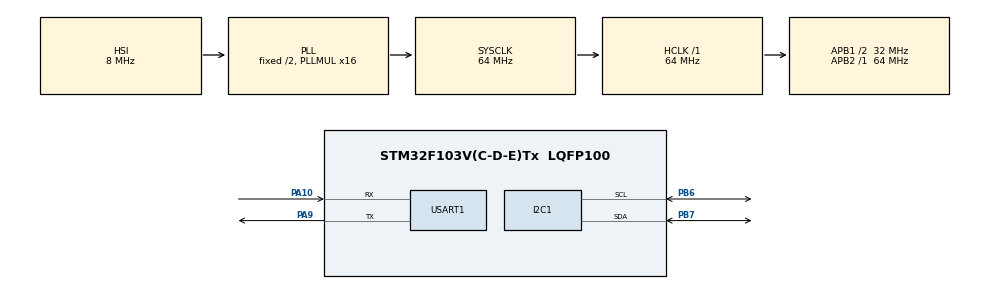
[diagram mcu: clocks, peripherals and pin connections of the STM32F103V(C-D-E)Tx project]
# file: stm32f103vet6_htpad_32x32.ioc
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Dma.Request0=USART1_RX
Dma.USART1_RX.0.Direction=DMA_PERIPH_TO_MEMORY
Dma.USART1_RX.0.Instance=DMA1_Channel5
Dma.USART1_RX.0.MemDataAlignment=DMA_MDATAALIGN_BYTE
Dma.USART1_RX.0.MemInc=DMA_MINC_ENABLE
Dma.USART1_RX.0.Mode=DMA_NORMAL
Dma.USART1_RX.0.PeriphDataAlignment=DMA_PDATAALIGN_BYTE
Dma.USART1_RX.0.PeriphInc=DMA_PINC_DISABLE
Dma.USART1_RX.0.Priority=DMA_PRIORITY_LOW
I2C1.I2C_Mode=I2C_Standard
I2C1.OwnAddress=0x1A
Mcu.Family=STM32F1
Mcu.Name=STM32F103V(C-D-E)Tx
Mcu.Package=LQFP100
NVIC.DMA1_Channel5_IRQn=true\:0\:0\:false\:false\:true\:false\:true\:true
NVIC.PriorityGroup=NVIC_PRIORITYGROUP_4
NVIC.TIM3_IRQn=true\:0\:0\:false\:false\:true\:true\:true\:true
NVIC.USART1_IRQn=true\:0\:0\:false\:false\:true\:true\:true\:true
PA10.Mode=Asynchronous
PA10.Signal=USART1_RX
PA9.Mode=Asynchronous
PA9.Signal=USART1_TX
PB6.Mode=I2C
PB6.Signal=I2C1_SCL
PB7.Mode=I2C
PB7.Signal=I2C1_SDA
ProjectManager.HeapSize=0x200
ProjectManager.StackSize=0x400
ProjectManager.TargetToolchain=STM32CubeIDE
RCC.AHBFreq_Value=64000000
RCC.APB1CLKDivider=RCC_HCLK_DIV2
RCC.APB1Freq_Value=32000000
RCC.APB1TimFreq_Value=64000000
RCC.APB2Freq_Value=64000000
RCC.APB2TimFreq_Value=64000000
RCC.HCLKFreq_Value=64000000
RCC.PLLMUL=RCC_PLL_MUL16
RCC.SYSCLKFreq_VALUE=64000000
RCC.SYSCLKSource=RCC_SYSCLKSOURCE_PLLCLK
RCC.USBFreq_Value=64000000
TIM3.Prescaler=64
USART1.VirtualMode=VM_ASYNC
VP_TIM3_VS_ClockSourceINT.Mode=Internal
board=custom

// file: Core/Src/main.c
/* USER CODE BEGIN Header */
/**
  ******************************************************************************
  * @file           : main.c
  * @brief          : Main program body
  ******************************************************************************
  * @attention
  *
  * Copyright (c) 2025 STMicroelectronics.
  * All rights reserved.
  *
  * This software is licensed under terms that can be found in the LICENSE file
  * in the root directory of this software component.
  * If no LICENSE file comes with this software, it is provided AS-IS.
  *
  ******************************************************************************
  */
/* USER CODE END Header */
#include "main.h"
#include "dma.h"
#include "i2c.h"
#include "tim.h"
#include "usart.h"
#include "gpio.h"

/* USER CODE BEGIN Includes */
#include "htpad_32x32.h"
#include <stdio.h>
#include "i2c_scan.h"
#include "uart_printf.h"
/* USER CODE END Includes */

void SystemClock_Config(void);

int main(void)
{

  /* MCU Configuration--------------------------------------------------------*/

  /* Reset of all peripherals, Initializes the Flash interface and the Systick. */
  HAL_Init();

  /* Configure the system clock */
  SystemClock_Config();

  /* Initialize all configured peripherals */
  MX_GPIO_Init();
  MX_DMA_Init();
  MX_I2C1_Init();
  MX_USART1_UART_Init();
  MX_TIM3_Init();
  /* USER CODE BEGIN 2 */
  printf("Application start!\n");
  uart_start_receive();

  setup();
  /* USER CODE END 2 */

  /* Infinite loop */
  /* USER CODE BEGIN WHILE */
  while (1)
  {
	  loop();
    /* USER CODE END WHILE */

  }
}

void SystemClock_Config(void)
{
  RCC_OscInitTypeDef RCC_OscInitStruct = {0};
  RCC_ClkInitTypeDef RCC_ClkInitStruct = {0};

  /** Initializes the RCC Oscillators according to the specified parameters
  * in the RCC_OscInitTypeDef structure.
  */
  RCC_OscInitStruct.OscillatorType = RCC_OSCILLATORTYPE_HSI;
  RCC_OscInitStruct.HSIState = RCC_HSI_ON;
  RCC_OscInitStruct.HSICalibrationValue = RCC_HSICALIBRATION_DEFAULT;
  RCC_OscInitStruct.PLL.PLLState = RCC_PLL_ON;
  RCC_OscInitStruct.PLL.PLLSource = RCC_PLLSOURCE_HSI_DIV2;
  RCC_OscInitStruct.PLL.PLLMUL = RCC_PLL_MUL16;
  if (HAL_RCC_OscConfig(&RCC_OscInitStruct) != HAL_OK)
  {
    Error_Handler();
  }

  /** Initializes the CPU, AHB and APB buses clocks
  */
  RCC_ClkInitStruct.ClockType = RCC_CLOCKTYPE_HCLK|RCC_CLOCKTYPE_SYSCLK
                              |RCC_CLOCKTYPE_PCLK1|RCC_CLOCKTYPE_PCLK2;
  RCC_ClkInitStruct.SYSCLKSource = RCC_SYSCLKSOURCE_PLLCLK;
  RCC_ClkInitStruct.AHBCLKDivider = RCC_SYSCLK_DIV1;
  RCC_ClkInitStruct.APB1CLKDivider = RCC_HCLK_DIV2;
  RCC_ClkInitStruct.APB2CLKDivider = RCC_HCLK_DIV1;

  if (HAL_RCC_ClockConfig(&RCC_ClkInitStruct, FLASH_LATENCY_2) != HAL_OK)
  {
    Error_Handler();
  }
}

/* USER CODE BEGIN 4 */

/**
  * @brief  Rx Transfer completed callback
  * @param  UartHandle: UART handle
  * @note   This example shows a simple way to report end of DMA Rx transfer, and
  *         you can add your own implementation.
  * @retval None
  */

/* USER CODE END 4 */

void Error_Handler(void)
{
  __disable_irq();
  while (1)
  {
  }
}
